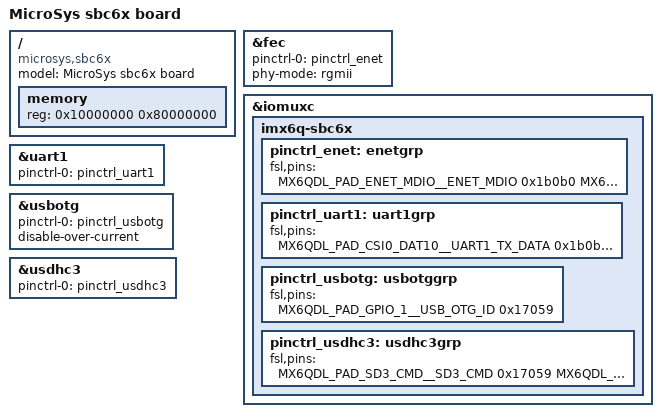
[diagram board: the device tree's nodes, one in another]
/*
 * Copyright 2013 Pavel Machek <pavel@denx.de>
 *
 * The code contained herein is licensed under the GNU General Public
 * License V2.
 */

/dts-v1/;
#include "imx6q.dtsi"

/ {
	model = "MicroSys sbc6x board";
	compatible = "microsys,sbc6x", "fsl,imx6q";

	memory {
		reg = <0x10000000 0x80000000>;
	};
};


&fec {
	pinctrl-names = "default";
	pinctrl-0 = <&pinctrl_enet>;
	phy-mode = "rgmii";
	status = "okay";
};

&iomuxc {
	imx6q-sbc6x {
		pinctrl_enet: enetgrp {
			fsl,pins = <
				MX6QDL_PAD_ENET_MDIO__ENET_MDIO		0x1b0b0
				MX6QDL_PAD_ENET_MDC__ENET_MDC		0x1b0b0
				MX6QDL_PAD_RGMII_TXC__RGMII_TXC		0x1b0b0
				MX6QDL_PAD_RGMII_TD0__RGMII_TD0		0x1b0b0
				MX6QDL_PAD_RGMII_TD1__RGMII_TD1		0x1b0b0
				MX6QDL_PAD_RGMII_TD2__RGMII_TD2		0x1b0b0
				MX6QDL_PAD_RGMII_TD3__RGMII_TD3		0x1b0b0
				MX6QDL_PAD_RGMII_TX_CTL__RGMII_TX_CTL	0x1b0b0
				MX6QDL_PAD_ENET_REF_CLK__ENET_TX_CLK	0x1b0b0
				MX6QDL_PAD_RGMII_RXC__RGMII_RXC		0x1b0b0
				MX6QDL_PAD_RGMII_RD0__RGMII_RD0		0x1b0b0
				MX6QDL_PAD_RGMII_RD1__RGMII_RD1		0x1b0b0
				MX6QDL_PAD_RGMII_RD2__RGMII_RD2		0x1b0b0
				MX6QDL_PAD_RGMII_RD3__RGMII_RD3		0x1b0b0
				MX6QDL_PAD_RGMII_RX_CTL__RGMII_RX_CTL	0x1b0b0
				MX6QDL_PAD_GPIO_16__ENET_REF_CLK	0x4001b0a8
			>;
		};

		pinctrl_uart1: uart1grp {
			fsl,pins = <
				MX6QDL_PAD_CSI0_DAT10__UART1_TX_DATA	0x1b0b1
				MX6QDL_PAD_CSI0_DAT11__UART1_RX_DATA	0x1b0b1
			>;
		};

		pinctrl_usbotg: usbotggrp {
			fsl,pins = <
				MX6QDL_PAD_GPIO_1__USB_OTG_ID		0x17059
			>;
		};

		pinctrl_usdhc3: usdhc3grp {
			fsl,pins = <
				MX6QDL_PAD_SD3_CMD__SD3_CMD		0x17059
				MX6QDL_PAD_SD3_CLK__SD3_CLK		0x10059
				MX6QDL_PAD_SD3_DAT0__SD3_DATA0		0x17059
				MX6QDL_PAD_SD3_DAT1__SD3_DATA1		0x17059
				MX6QDL_PAD_SD3_DAT2__SD3_DATA2		0x17059
				MX6QDL_PAD_SD3_DAT3__SD3_DATA3		0x17059
			>;
		};
	};
};

&uart1 {
	pinctrl-names = "default";
	pinctrl-0 = <&pinctrl_uart1>;
	status = "okay";
};

&usbotg {
	pinctrl-names = "default";
	pinctrl-0 = <&pinctrl_usbotg>;
	disable-over-current;
	status = "okay";
};

&usdhc3 {
	pinctrl-names = "default";
	pinctrl-0 = <&pinctrl_usdhc3>;
	status = "okay";
};
